# R7FA6M3AH register map
Vendor: Renesas; Series: RA6; File version: 1.2
CPU: CM4 r0p1, little endian, MPU, FPU, VTOR, 4 interrupt priority bits
Registers are 32-bit, read-write, reset 0x0 unless marked. A register's access mark holds for its fields unless they carry their own. Offsets are from the block's base; [hi:lo] are bit positions.

## EDMAC0 — DMA Controller for the Ethernet Controller Channel 0
Base 0x40064000
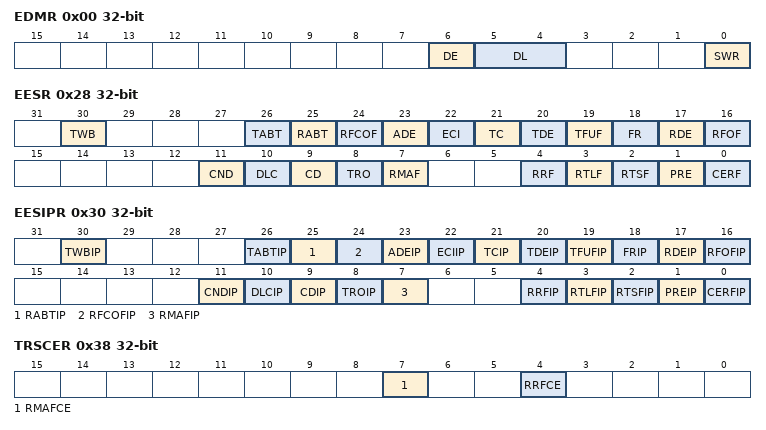
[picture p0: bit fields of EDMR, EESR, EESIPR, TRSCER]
0x00 EDMR — EDMAC Mode Register
  [6] DE — Big Endian Mode/Little Endian ModeNOTE: This setting applies to data for the transmit/receive buffer. It does not apply to transmit/receive descriptors and registers.
  [5:4] DL — Transmit/Receive DescriptorLength
  [0] SWR wo — Software Reset
0x08 EDTRR — EDMAC Transmit Request Register
  [0] TR wo — Transmit Request
0x10 EDRRR — EDMAC Receive Request Register
  [0] RR — Receive Request
0x18 TDLAR — Transmit Descriptor List Start Address Register
  [31:0] TDLAR — The start address of the transmit descriptor list is set. Set the start address according to the descriptor length selected by the EDMR.DL[1:0] bits.16-byte boundary: Lower 4 bits = 0000b32-byte boundary: Lower 5 bits = 00000b64-byte boundary: Lower 6 bits = 000000b
0x20 RDLAR — Receive Descriptor List Start Address Register
  [31:0] RDLAR — The start address of the receive descriptor list is set. Set the start address according to the descriptor length selected by the EDMR.DL[1:0] bits.16-byte boundary: Lower 4 bits = 0000b32-byte boundary: Lower 5 bits = 00000b64-byte boundary: Lower 6 bits = 000000b
0x28 EESR — ETHERC/EDMAC Status Register
  [30] TWB write-1-clears read-modifies — Write,Back Complete Flag
  [26] TABT write-1-clears read-modifies — Transmit Abort Detect Flag
  [25] RABT write-1-clears read-modifies — Receive Abort Detect Flag
  [24] RFCOF write-1-clears read-modifies — Receive Frame Counter Overflow Flag
  [23] ADE write-1-clears read-modifies — Address Error Flag
  [22] ECI ro — ETHERC Status Register Source FlagNOTE: When the source in the ETHERCn.ECSR register is cleared, the ECI flag is also cleared.
  [21] TC write-1-clears read-modifies — Frame Transfer Complete Flag
  [20] TDE write-1-clears read-modifies — Transmit Descriptor Empty Flag
  [19] TFUF write-1-clears read-modifies — Transmit FIFO Underflow Flag
  [18] FR write-1-clears read-modifies — Frame Receive Flag
  [17] RDE write-1-clears read-modifies — Receive Descriptor Empty Flag
  [16] RFOF write-1-clears read-modifies — Receive FIFO Overflow Flag
  [11] CND write-1-clears read-modifies — Carrier Not Detect Flag
  [10] DLC write-1-clears read-modifies — Loss of Carrier Detect Flag
  [9] CD write-1-clears read-modifies — Late Collision Detect Flag
  [8] TRO write-1-clears read-modifies — Transmit Retry Over Flag
  [7] RMAF write-1-clears read-modifies — Multicast Address Frame Receive Flag
  [4] RRF write-1-clears read-modifies — Alignment Error Flag
  [3] RTLF write-1-clears read-modifies — Frame,Too,Long Error Flag
  [2] RTSF write-1-clears read-modifies — Frame,Too,Short Error Flag
  [1] PRE write-1-clears read-modifies — PHY,LSI Receive Error Flag
  [0] CERF write-1-clears read-modifies — CRC Error Flag
0x30 EESIPR — ETHERC/EDMAC Status Interrupt Enable Register
  [30] TWBIP — Write,Back Complete Interrupt Request Enable
  [26] TABTIP — Transmit Abort Detect Interrupt Request Enable
  [25] RABTIP — Receive Abort Detect Interrupt Request Enable
  [24] RFCOFIP — Receive Frame Counter Overflow Interrupt Request Enable
  [23] ADEIP — Address Error Interrupt Request Enable
  [22] ECIIP — ETHERC Status Register Source Interrupt Request Enable
  [21] TCIP — Frame Transfer Complete Interrupt Request Enable
  [20] TDEIP — Transmit Descriptor Empty Interrupt Request Enable
  [19] TFUFIP — Transmit FIFO Underflow Interrupt Request Enable
  [18] FRIP — Frame Receive Interrupt Request Enable
  [17] RDEIP — Receive Descriptor Empty Interrupt Request Enable
  [16] RFOFIP — Receive FIFO Overflow Interrupt Request Enable
  [11] CNDIP — Carrier Not Detect Interrupt Request Enable
  [10] DLCIP — Loss of Carrier Detect Interrupt Request Enable
  [9] CDIP — Late Collision Detect Interrupt Request Enable
  [8] TROIP — Transmit Retry Over Interrupt Request Enable
  [7] RMAFIP — Multicast Address Frame Receive Interrupt Request Enable
  [4] RRFIP — Alignment Error Interrupt Request Enable
  [3] RTLFIP — Frame,Too,Long Error Interrupt Request Enable
  [2] RTSFIP — Frame,Too,Short Error Interrupt Request Enable
  [1] PREIP — PHY,LSI Receive Error Interrupt Request Enable
  [0] CERFIP — CRC Error Interrupt Request Enable
0x38 TRSCER — ETHERC/EDMAC Transmit/Receive Status Copy Enable Register
  [7] RMAFCE — RMAF Flag Copy Enable
  [4] RRFCE — RRF Flag Copy Enable
0x40 RMFCR — Missed,Frame Counter Register
  [15:0] MFC write-clears — Missed,Frame CounterThese bits indicate the number of frames that are discarded and not transferred to the receive buffer during reception.
0x48 TFTR — Transmit FIFO Threshold Register
  [10:0] TFT range 0x000..0x200 — Transmit FIFO Threshold00Dh to 200h: The threshold is the set value multiplied by 4. Example: 00Dh: 52 bytes 040h: 256 bytes 100h: 1024 bytes 200h: 2048 bytes
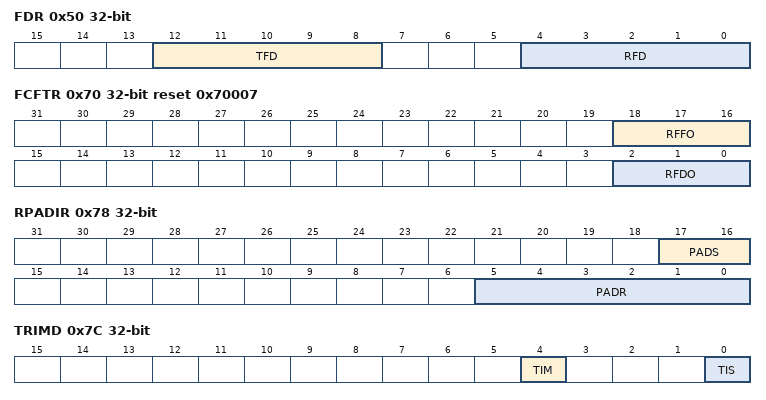
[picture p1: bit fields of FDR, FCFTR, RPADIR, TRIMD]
0x50 FDR — Transmit FIFO Threshold Register
  [12:8] TFD — Receive FIFO Depth
  [4:0] RFD — Transmit FIFO Depth
0x58 RMCR — Receive Method Control Register
  [0] RNR — Receive Request Reset
0x64 TFUCR — Transmit FIFO Underflow Counter
  [15:0] UNDER — Transmit FIFO Underflow CountThese bits indicate how many times the transmit FIFO has underflowed. The counter stops when the counter value reaches FFFFh.
0x68 RFOCR — Receive FIFO Overflow Counter
  [15:0] OVER — Receive FIFO Overflow CountThese bits indicate how many times the receive FIFO has overflowed. The counter stops when the counter value reaches FFFFh.
0x6C IOSR — Independent Output Signal Setting Register
  [0] ELB — External Loopback Mode
0x70 FCFTR reset 0x70007 — Flow Control Start FIFO Threshold Setting Register
  [18:16] RFFO — Receive FIFO Frame PAUSE Output Threshold(When ((RFFO+1)x2) receive frames have been stored in the receive FIFO.)
  [2:0] RFDO — Receive FIFO Data PAUSE Output Threshold(When (RFDO+1)x256-32 bytes of data is stored in the receive FIFO.)
0x78 RPADIR — Receive Data Padding Insert Register
  [17:16] PADS — Padding Size
  [5:0] PADR — Padding Slot
0x7C TRIMD — Transmit Interrupt Setting Register
  [4] TIM — Transmit Interrupt Mode
  [0] TIS — Transmit Interrupt EnableSet the EESR.TWB flag to 1 in the mode selected by the TIM bit to notify an interrupt.
0xC8 RBWAR ro — Receive Buffer Write Address Register
  [31:0] RBWAR — Receive Buffer Write Address RegisterThe RBWAR register indicates the last address that the EDMAC has written data to when writing to the receive buffer.Refer to the address indicated by the RBWAR register to recognize which address in the receive buffer the EDMAC is writing data to. Note that the address that the EDMAC is outputting to the receive buffer may not match the read value of the RBWAR register during data reception.
0xCC RDFAR ro — Receive Descriptor Fetch Address Register
  [31:0] RDFAR — Receive Descriptor Fetch Address RegisterThe RDFAR register indicates the start address of the last fetched receive descriptor when the EDMAC fetches descriptor information from the receive descriptor.Refer to the address indicated by the RDFAR register to recognize which receive descriptor information the EDMAC is using for the current processing. Note that the address of the receive descriptor that the EDMAC fetches may not match the read value of the RDFAR register during data reception.
0xD4 TBRAR ro — Transmit Buffer Read Address Register
  [31:0] TBRAR — Transmit Buffer Read Address RegisterThe TBRAR register indicates the last address that the EDMAC has read data from when reading data from the transmit buffer.Refer to the address indicated by the TBRAR register to recognize which address in the transmit buffer the EDMAC is reading from. Note that the address that the EDMAC is outputting to the transmit buffer may not match the read value of the TBRAR register.
0xD8 TDFAR ro — Transmit Descriptor Fetch Address Register
  [31:0] TDFAR — Transmit Descriptor Fetch Address RegisterThe TDFAR register indicates the start address of the last fetched transmit descriptor when the EDMAC fetches descriptor information from the transmit descriptor.Refer to the address indicated by the TDFAR register to recognize which transmit descriptor information the EDMAC is using for the current processing. Note that the address of the transmit descriptor that the EDMAC fetches may not match the read value of the TDFAR register.

## PTPEDMAC — DMA Controller for EPTPC
Base 0x40064400
Registers as EDMAC0, without TRSCER; these are added or differ:
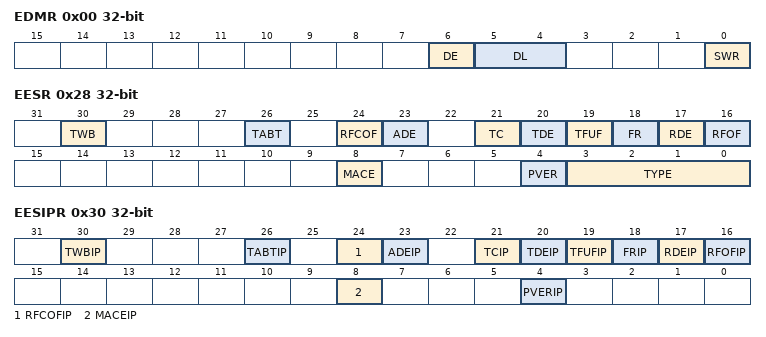
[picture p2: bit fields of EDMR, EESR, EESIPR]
0x00 EDMR — PTPEDMAC Mode Register
  [6] DE — Big Endian Mode/Little Endian ModeNOTE: This setting applies to data for the transmit/receive buffer. It does not apply to transmit/receive descriptors and registers.
  [5:4] DL — Transmit/Receive DescriptorLength
  [0] SWR — Software Reset (The read value is 0.)
0x08 EDTRR — EDMAC Transmit Request Register
  [0] TR — Transmit Request (The read value is 0.)
0x28 EESR — PTP/EDMAC Status Register
  [30] TWB write-1-clears read-modifies — Write,Back Complete Flag
  [26] TABT write-1-clears read-modifies — Transmit Abort Detect Flag
  [24] RFCOF write-1-clears read-modifies — Receive Frame Counter Overflow Flag
  [23] ADE write-1-clears read-modifies — Address Error Flag
  [21] TC write-1-clears read-modifies — Frame Transfer Complete Flag
  [20] TDE write-1-clears read-modifies — Transmit Descriptor Empty Flag
  [19] TFUF write-1-clears read-modifies — Transmit FIFO Underflow Flag
  [18] FR write-1-clears read-modifies — Frame Receive Flag
  [17] RDE write-1-clears read-modifies — Receive Descriptor Empty Flag
  [16] RFOF write-1-clears read-modifies — Receive FIFO Overflow Flag
  [8] MACE write-1-clears read-modifies — MAC Address Mismatch Flag
  [4] PVER write-1-clears read-modifies — PTP v2 Packet Flag
  [3:0] TYPE write-1-clears read-modifies — PTP v2 Message Type Flag
0x30 EESIPR — PTP/EDMAC Status Interrupt Enable Register
  [30] TWBIP — Write,Back Complete Interrupt Request Enable
  [26] TABTIP — Transmit Abort Detect Interrupt Request Enable
  [24] RFCOFIP — Receive Frame Counter Overflow Interrupt Request Enable
  [23] ADEIP — Address Error Interrupt Request Enable
  [21] TCIP — Frame Transfer Complete Interrupt Request Enable
  [20] TDEIP — Transmit Descriptor Empty Interrupt Request Enable
  [19] TFUFIP — Transmit FIFO Underflow Interrupt Request Enable
  [18] FRIP — Frame Receive Interrupt Request Enable
  [17] RDEIP — Receive Descriptor Empty Interrupt Request Enable
  [16] RFOFIP — Receive FIFO Overflow Interrupt Request Enable
  [8] MACEIP — MAC Address Mismatch Interrupt Request Enable
  [4] PVERIP — PTP v2 Packet Receive Interrupt Request Enable
0x48 TFTR — Transmit FIFO Threshold Register
  [10:0] TFT — Transmit FIFO Threshold00Dh to 200h: The threshold is the set value multiplied by 4. Example: 00Dh: 52 bytes 040h: 256 bytes 100h: 1024 bytes 200h: 2048 bytes
